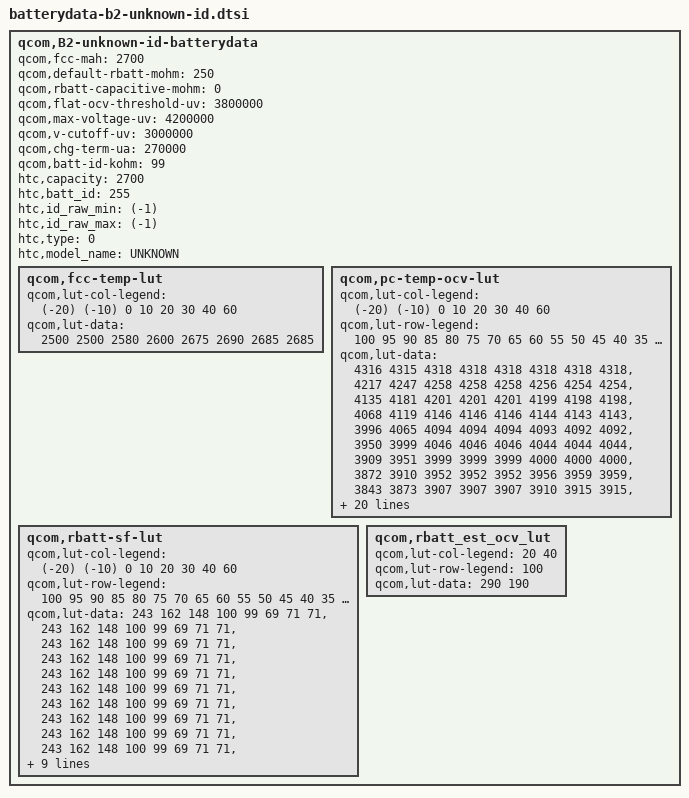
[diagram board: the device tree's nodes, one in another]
	qcom,B2-unknown-id-batterydata {
	qcom,fcc-mah = <2700>;
	qcom,default-rbatt-mohm = <250>;
	qcom,rbatt-capacitive-mohm = <0>;
	qcom,flat-ocv-threshold-uv = <3800000>;
	qcom,max-voltage-uv = <4200000>;
	qcom,v-cutoff-uv = <3000000>;
	qcom,chg-term-ua = <270000>;
	qcom,batt-id-kohm = <99>;
	htc,capacity = <2700>;
	htc,batt_id = <255>;
	htc,id_raw_min = <(-1)>;
	htc,id_raw_max = <(-1)>;
	htc,type = <0>;
	htc,model_name = "UNKNOWN";

	qcom,fcc-temp-lut {
		qcom,lut-col-legend = <(-20) (-10) 0 10 20 30 40 60>;
		qcom,lut-data = <2500 2500 2580 2600 2675 2690 2685 2685>;
	};

	qcom,pc-temp-ocv-lut {
		qcom,lut-col-legend = <(-20) (-10) 0 10 20 30 40 60>;
		qcom,lut-row-legend = <100 95 90 85 80 75 70 65 60 55 50 45 40 35 30 25 20 15 10 9 8 7 6 5 4 3 2 1 0>;
		qcom,lut-data = <4316 4315 4318 4318 4318 4318 4318 4318>,
				<4217 4247 4258 4258 4258 4256 4254 4254>,
				<4135 4181 4201 4201 4201 4199 4198 4198>,
				<4068 4119 4146 4146 4146 4144 4143 4143>,
				<3996 4065 4094 4094 4094 4093 4092 4092>,
				<3950 3999 4046 4046 4046 4044 4044 4044>,
				<3909 3951 3999 3999 3999 4000 4000 4000>,
				<3872 3910 3952 3952 3952 3956 3959 3959>,
				<3843 3873 3907 3907 3907 3910 3915 3915>,
				<3822 3839 3870 3870 3870 3870 3872 3872>,
				<3805 3811 3842 3842 3842 3841 3842 3842>,
				<3790 3790 3820 3820 3820 3819 3819 3819>,
				<3775 3775 3801 3801 3801 3801 3801 3801>,
				<3759 3762 3786 3786 3786 3786 3786 3786>,
				<3742 3748 3771 3771 3771 3770 3769 3769>,
				<3721 3731 3755 3755 3755 3749 3744 3744>,
				<3697 3710 3735 3735 3735 3728 3723 3723>,
				<3667 3678 3705 3705 3705 3698 3693 3693>,
				<3628 3629 3674 3674 3674 3671 3667 3667>,
				<3617 3611 3670 3670 3670 3666 3662 3662>,
				<3606 3593 3665 3665 3665 3661 3657 3657>,
				<3595 3575 3655 3655 3655 3644 3641 3641>,
				<3584 3557 3646 3646 3646 3628 3625 3625>,
				<3573 3539 3608 3608 3608 3577 3577 3577>,
				<3558 3522 3570 3570 3570 3527 3528 3528>,
				<3543 3505 3498 3498 3498 3436 3442 3442>,
				<3528 3488 3427 3427 3427 3345 3357 3357>,
				<3512 3472 3210 3210 3210 3073 3071 3071>,
				<3497 3455 3000 3000 3000 3000 3000 3000>;
	};

	qcom,rbatt-sf-lut {
		qcom,lut-col-legend = <(-20) (-10) 0 10 20 30 40 60>;
		qcom,lut-row-legend = <100 95 90 85 80 75 70 65 60 55 50 45 40 35 30 25 20 15 10>;
		qcom,lut-data = <243 162 148 100 99 69 71 71>,
                                        <243 162 148 100 99 69 71 71>,
                                        <243 162 148 100 99 69 71 71>,
                                        <243 162 148 100 99 69 71 71>,
                                        <243 162 148 100 99 69 71 71>,
                                        <243 162 148 100 99 69 71 71>,
                                        <243 162 148 100 99 69 71 71>,
                                        <243 162 148 100 99 69 71 71>,
                                        <243 162 148 100 99 69 71 71>,
                                        <243 162 148 100 99 69 71 71>,
                                        <243 162 148 100 99 69 71 71>,
                                        <243 162 148 100 99 69 71 71>,
                                        <243 162 148 100 99 69 71 71>,
                                        <243 162 148 100 99 69 71 71>,
                                        <243 162 148 100 99 69 71 71>,
                                        <243 162 148 100 99 69 71 71>,
                                        <243 162 148 100 99 69 71 71>,
                                        <243 162 148 100 99 69 71 71>,
                                        <243 162 148 100 99 69 71 71>;
		};

	qcom,rbatt_est_ocv_lut {
		qcom,lut-col-legend = <20 40>;
		qcom,lut-row-legend = <100>;
		qcom,lut-data = <290 190>;
		};
	};
